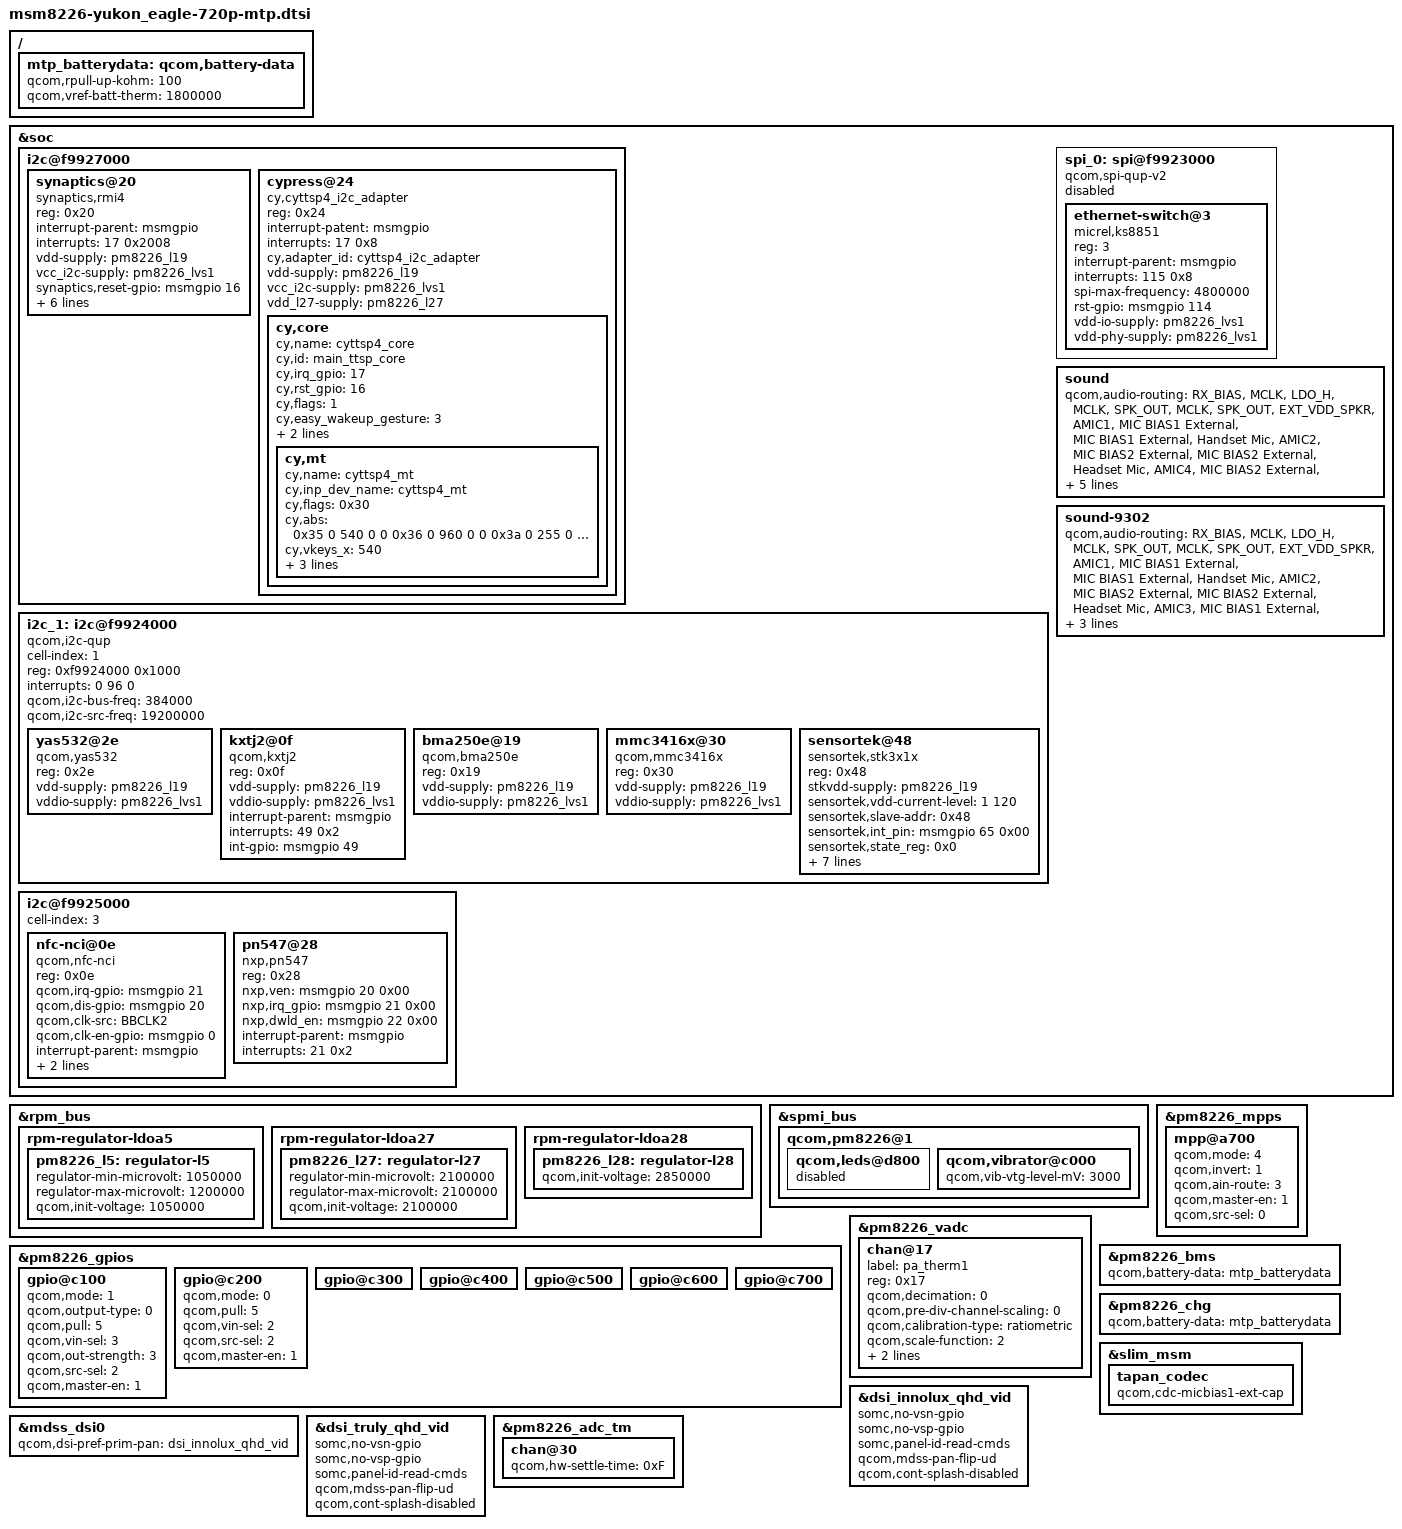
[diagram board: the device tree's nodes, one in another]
/* Copyright (c) 2013, The Linux Foundation. All rights reserved.
 *
 * This program is free software; you can redistribute it and/or modify
 * it under the terms of the GNU General Public License version 2 and
 * only version 2 as published by the Free Software Foundation.
 *
 * This program is distributed in the hope that it will be useful,
 * but WITHOUT ANY WARRANTY; without even the implied warranty of
 * MERCHANTABILITY or FITNESS FOR A PARTICULAR PURPOSE.  See the
 * GNU General Public License for more details.
 */

/include/ "msm8226-yukon_common.dtsi"
/include/ "msm8226-yukon_eagle-camera-sensor-mtp.dtsi"

/include/ "dsi-panel-eagle.dtsi"

&soc {


	i2c@f9927000 { /* BLSP1 QUP5 */
		synaptics@20 {
			compatible = "synaptics,rmi4";
			reg = <0x20>;
			interrupt-parent = <&msmgpio>;
			interrupts = <17 0x2008>;
			vdd-supply = <&pm8226_l19>;
			vcc_i2c-supply = <&pm8226_lvs1>;
			synaptics,reset-gpio = <&msmgpio 16 0x00>;
			synaptics,irq-gpio = <&msmgpio 17 0x2008>;
			synaptics,button-map = <139 102 158>;
			synaptics,fw-image-name = "PR1468813.img";
			synaptics,i2c-pull-up;
			synaptics,power-down;
			synaptics,disable-gpios;
		};
		cypress@24 {
			compatible = "cy,cyttsp4_i2c_adapter";
			reg = <0x24>;
			interrupt-patent = <&msmgpio>;
			interrupts = <17 0x8>;
			cy,adapter_id = "cyttsp4_i2c_adapter";
			vdd-supply = <&pm8226_l19>;
			vcc_i2c-supply = <&pm8226_lvs1>;
			vdd_l27-supply = <&pm8226_l27>;

			cy,core {
				cy,name = "cyttsp4_core";
				cy,id = "main_ttsp_core";

				cy,irq_gpio = <17>;
				cy,rst_gpio = <16>;

				/* Enable cy,max_xfer_len to limit max I2C/SPI transfer length */
				/* cy,max_xfer_len = <0x100>; */

				/* CY_CORE_FLAG_WAKE_ON_GESTURE */
				cy,flags = <1>;
				/* CY_CORE_EWG_TAP_TAP | CY_CORE_EWG_TWO_FINGER_SLIDE */
				cy,easy_wakeup_gesture = <3>;
				cy,btn_keys = <102 /* KEY_HOME */
						139 /* KEY_MENU */
						158 /* KEY_BACK */
						217 /* KEY_SEARCH */
						114 /* KEY_VOLUMEDOWN */
						115 /* KEY_VOLUMEUP */
						212 /* KEY_CAMERA */
						116>; /* KEY_POWER */
				cy,btn_keys-tag = <0>;

				cy,mt {
					cy,name = "cyttsp4_mt";
					cy,inp_dev_name = "cyttsp4_mt";
					/* CY_MT_FLAG_FLIP | CY_MT_FLAG_INV_X | CY_MT_FLAG_INV_Y */
					cy,flags = <0x30>;
					cy,abs =
						/* ABS_MT_POSITION_X, CY_ABS_MIN_X, CY_ABS_MAX_X, 0, 0 */
						<0x35 0 540 0 0
						/* ABS_MT_POSITION_Y, CY_ABS_MIN_Y, CY_ABS_MAX_Y, 0, 0 */
						0x36 0 960 0 0
						/* ABS_MT_PRESSURE, CY_ABS_MIN_P, CY_ABS_MAX_P, 0, 0 */
						0x3a 0 255 0 0
						/* CY_IGNORE_VALUE, CY_ABS_MIN_W, CY_ABS_MAX_W, 0, 0 */
						0xffff 0 255 0 0
						/* ABS_MT_TRACKING_ID, CY_ABS_MIN_T, CY_ABS_MAX_T, 0, 0 */
						0x39 0 15 0 0
						/* ABS_MT_TOUCH_MAJOR, 0, 255, 0, 0 */
						0x30 0 255 0 0
						/* ABS_MT_TOUCH_MINOR, 0, 255, 0, 0 */
						0x31 0 255 0 0
						/* ABS_MT_ORIENTATION, -128, 127, 0, 0 */
						0x34 0xfffffed7 127 0 0>;

					cy,vkeys_x = <540>;
					cy,vkeys_y = <960>;

					cy,virtual_keys = /* KeyCode CenterX CenterY Width Height */
						/* KEY_BACK */
						<158 1360 90 160 180
						/* KEY_MENU */
						139 1360 270 160 180
						/* KEY_HOME */
						102 1360 450 160 180
						/* KEY SEARCH */
						217 1360 630 160 180>;
				};
			};
		};
	};

	i2c@f9924000 { /* BLSP1 QUP2 */
		#address-cells = <1>;
		#size-cells = <0>;
		cell-index = <2>;
		compatible = "qcom,i2c-qup";
		reg = <0xf9924000 0x1000>;
		reg-names = "qup_phys_addr";
		interrupts = <0 96 0>;
		interrupt-names = "qup_err_intr";
		qcom,i2c-bus-freq = <400000>;
		qcom,i2c-src-freq = <19200000>;

		yas532@2e {
			compatible = "qcom,yas532";
			reg = <0x2e>;
			vdd-supply = <&pm8226_l19>;
			vddio-supply = <&pm8226_lvs1>;
		};
		kxtj2@0f {
			compatible = "qcom,kxtj2";
			reg = <0x0f>;
			vdd-supply = <&pm8226_l19>;
			vddio-supply = <&pm8226_lvs1>;
			interrupt-parent = <&msmgpio>;
			interrupts = <49 0x2>;
			int-gpio = <&msmgpio 49 0x00>;
		};
		bma250e@19 {
			compatible = "qcom,bma250e";
			reg = <0x19>;
			vdd-supply = <&pm8226_l19>;
			vddio-supply = <&pm8226_lvs1>;
		};
		mmc3416x@30 {
			compatible = "qcom,mmc3416x";
			reg = <0x30>;
			vdd-supply = <&pm8226_l19>;
			vddio-supply = <&pm8226_lvs1>;
		};
		sensortek@48 {
			compatible = "sensortek,stk3x1x";
			reg = <0x48>;
			stkvdd-supply = <&pm8226_l19>;
			sensortek,vdd-current-level = <1 120>;
			sensortek,slave-addr = <0x48>;
			sensortek,int_pin = <&msmgpio 65 0x00>;
			sensortek,state_reg = <0x0>;
			sensortek,psctrl_reg = <0x33>;
			sensortek,alsctrl_reg = <0x39>;
			sensortek,ledctrl_reg = <0xFF>;
			sensortek,wait_reg = <0x9>;
			sensortek,ps_thd_h = <0x6A4>;//1700
			sensortek,ps_thd_l = <0x5DC>;//1500
			sensortek,transmittance = <0x458>;//1112
		};
	};

	i2c@f9925000 { /* BLSP1 QUP3 */
		cell-index = <3>;
		nfc-nci@0e {
			compatible = "qcom,nfc-nci";
			reg = <0x0e>;
			qcom,irq-gpio = <&msmgpio 21 0x00>;
			qcom,dis-gpio = <&msmgpio 20 0x00>;
			qcom,clk-src = "BBCLK2";
			qcom,clk-en-gpio = <&msmgpio 0 0x00>;
			interrupt-parent = <&msmgpio>;
			interrupts = <21 0>;
			qcom,clk-gpio = <&pm8226_gpios 3 0>;
		};
	};

	spi@f9923000 {
		ethernet-switch@3 {
			compatible = "micrel,ks8851";
			reg = <3>;
			interrupt-parent = <&msmgpio>;
			interrupts = <115 0x8>;
			spi-max-frequency = <4800000>;
			rst-gpio = <&msmgpio 114 0>;
			vdd-io-supply = <&pm8226_lvs1>;
			vdd-phy-supply = <&pm8226_lvs1>;
		};
	};

	sound {
		qcom,audio-routing =
			"RX_BIAS", "MCLK",
			"LDO_H", "MCLK",
			"SPK_OUT", "MCLK",
			"SPK_OUT", "EXT_VDD_SPKR",
			"AMIC1", "MIC BIAS1 External",
			"MIC BIAS1 External", "Handset Mic",
			"AMIC2", "MIC BIAS2 External",
			"MIC BIAS2 External", "Headset Mic",
			"AMIC4", "MIC BIAS2 External",
			"MIC BIAS2 External", "ANCRight Headset Mic",
			"AMIC5", "MIC BIAS2 External",
			"MIC BIAS2 External", "ANCLeft Headset Mic";

		qcom,cdc-mclk-gpios = <&pm8226_gpios 1 0>;
		qcom,cdc-vdd-spkr-gpios = <&pm8226_gpios 2 0>;
	};

	sound-9302 {
		qcom,audio-routing =
			"RX_BIAS", "MCLK",
			"LDO_H", "MCLK",
			"SPK_OUT", "MCLK",
			"SPK_OUT", "EXT_VDD_SPKR",
			"AMIC1", "MIC BIAS1 External",
			"MIC BIAS1 External", "Handset Mic",
			"AMIC2", "MIC BIAS2 External",
			"MIC BIAS2 External", "Headset Mic",
			"AMIC3", "MIC BIAS1 External",
			"MIC BIAS1 External", "Handset Mic";

		qcom,cdc-mclk-gpios = <&pm8226_gpios 1 0>;
		qcom,cdc-vdd-spkr-gpios = <&pm8226_gpios 2 0>;
	};

        i2c_1: i2c@f9924000 { /* BLSP-1 QUP-2 */
                cell-index = <1>;
                compatible = "qcom,i2c-qup";
                reg = <0xf9924000 0x1000>;
                #address-cells = <1>; 
                #size-cells = <0>;
                reg-names = "qup_phys_addr";
                interrupts = <0 96 0>;
                interrupt-names = "qup_err_intr";
		qcom,i2c-bus-freq = <384000>;
                qcom,i2c-src-freq = <19200000>;
        };
       
       i2c@f9925000 { /* BLSP-1 QUP-3 */
       pn547@28 {
			compatible = "nxp,pn547";
			reg = <0x28>;
			nxp,ven = <&msmgpio 20 0x00>;
			nxp,irq_gpio = <&msmgpio 21 0x00>;
			nxp,dwld_en = <&msmgpio 22 0x00>;
			interrupt-parent = <&msmgpio>;
			interrupts = <21 0x2>;
		};
       };
	spi_0: spi@f9923000 { /* BLSP1 QUP1 */
		compatible = "qcom,spi-qup-v2";
		status = "disabled";
	};
};

&rpm_bus {
	rpm-regulator-ldoa5 {
		pm8226_l5: regulator-l5 {
			regulator-min-microvolt = <1050000>;
			regulator-max-microvolt = <1200000>;
			qcom,init-voltage = <1050000>;
		};
	};

	rpm-regulator-ldoa27 {
		pm8226_l27: regulator-l27 {
			regulator-min-microvolt = <2100000>;
			regulator-max-microvolt = <2100000>;
			qcom,init-voltage = <2100000>;
		};
	};

	rpm-regulator-ldoa28 {
		pm8226_l28: regulator-l28 {
			qcom,init-voltage = <2850000>;
		};
	};
};

&spmi_bus {
	qcom,pm8226@1 {
		qcom,leds@d800 {
			status = "disabled";
		};
		qcom,vibrator@c000 {
			qcom,vib-vtg-level-mV = <3000>;
		};
	};
};

&pm8226_gpios {
	gpio@c100 { /* GPIO 2 */
		qcom,mode = <1>;
		qcom,output-type = <0>;
		qcom,pull = <5>;
		qcom,vin-sel = <3>;
		qcom,out-strength = <3>;
		qcom,src-sel = <2>;
		qcom,master-en = <1>;
	};

	gpio@c200 { /* GPIO 3 */
		qcom,mode = <0>;		/* QPNP_PIN_MODE_DIG_IN */
		qcom,pull = <5>;		/* QPNP_PIN_PULL_NO */
		qcom,vin-sel = <2>;		/* QPNP_PIN_VIN2 */
		qcom,src-sel = <2>;		/* QPNP_PIN_SEL_FUNC_1 */
		qcom,master-en = <1>;
	};

	gpio@c300 { /* GPIO 4 */
	};

	gpio@c400 { /* GPIO 5 */
	};

	gpio@c500 { /* GPIO 6 */
	};

	gpio@c600 { /* GPIO 7 */
	};

	gpio@c700 { /* GPIO 8 */
	};
};

&pm8226_mpps {
	mpp@a700 { /* MPP 8 */
		/* PA_THERM1 config */
		qcom,mode = <4>; /* AIN input */
		qcom,invert = <1>; /* Enable MPP */
		qcom,ain-route = <3>; /* AMUX 8 */
		qcom,master-en = <1>;
		qcom,src-sel = <0>; /* Function constant */
	};
};

&pm8226_vadc {
	chan@17 {
		label = "pa_therm1";
		reg = <0x17>;
		qcom,decimation = <0>;
		qcom,pre-div-channel-scaling = <0>;
		qcom,calibration-type = "ratiometric";
		qcom,scale-function = <2>;
		qcom,hw-settle-time = <2>;
		qcom,fast-avg-setup = <0>;
	};
};

/ {
	mtp_batterydata: qcom,battery-data {
		qcom,rpull-up-kohm = <100>;
		qcom,vref-batt-therm = <1800000>;

		/include/ "batterydata-palladium.dtsi"
		/include/ "batterydata-mtp-3000mah.dtsi"
	};
};

&pm8226_bms {
	qcom,battery-data = <&mtp_batterydata>;
};

&pm8226_chg {
	qcom,battery-data = <&mtp_batterydata>;
};

&slim_msm {
	tapan_codec {
		qcom,cdc-micbias1-ext-cap;
	};
};

&mdss_dsi0 {
	qcom,dsi-pref-prim-pan = <&dsi_innolux_qhd_vid>;
};

&dsi_innolux_qhd_vid {
	somc,no-vsn-gpio;
	somc,no-vsp-gpio;
	somc,panel-id-read-cmds;
	qcom,mdss-pan-flip-ud;
	qcom,cont-splash-disabled;
};

&dsi_truly_qhd_vid {
	somc,no-vsn-gpio;
	somc,no-vsp-gpio;
	somc,panel-id-read-cmds;
	qcom,mdss-pan-flip-ud;
	qcom,cont-splash-disabled;
};


&pm8226_adc_tm {
	/* Channel Node */
	chan@30 {
		qcom,hw-settle-time = <0xF>;
	};
};
